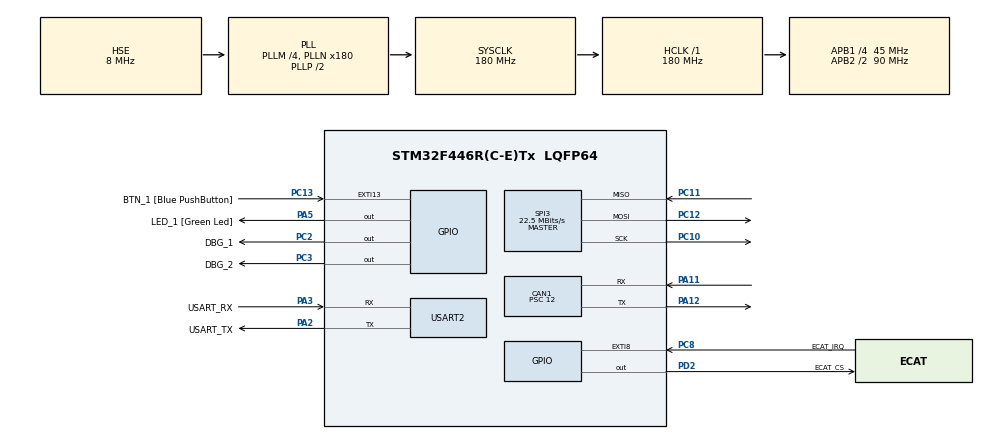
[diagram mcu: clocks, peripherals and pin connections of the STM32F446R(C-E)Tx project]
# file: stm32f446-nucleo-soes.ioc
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CAN1.AWUM=DISABLE
CAN1.BS1=CAN_BS1_12TQ
CAN1.BS2=CAN_BS2_2TQ
CAN1.CalculateBaudRate=250000
CAN1.CalculateTimeBit=4000
CAN1.CalculateTimeQuantum=266.6666666666667
CAN1.NART=DISABLE
CAN1.Prescaler=12
CAN1.RFLM=DISABLE
CAN1.SJW=CAN_SJW_1TQ
Mcu.Family=STM32F4
Mcu.Name=STM32F446R(C-E)Tx
Mcu.Package=LQFP64
Mcu.UserConstants=ecat_spi,$$_SPI3_IP_HANDLE_$$;printf_uart,$$_USART2_IP_HANDLE_$$
NVIC.CAN1_RX0_IRQn=true\:0\:0\:false\:false\:true\:true\:true\:true
NVIC.EXTI15_10_IRQn=true\:0\:0\:false\:false\:true\:true\:true\:true
NVIC.EXTI9_5_IRQn=true\:0\:0\:false\:false\:true\:true\:true\:true
NVIC.PriorityGroup=NVIC_PRIORITYGROUP_2
NVIC.TIM7_IRQn=true\:0\:0\:true\:false\:true\:true\:true\:true
PA11.Mode=CAN_Activate
PA11.Signal=CAN1_RX
PA12.Mode=CAN_Activate
PA12.Signal=CAN1_TX
PA13.GPIO_Label=TMS
PA13.Mode=Serial_Wire
PA13.Signal=SYS_JTMS-SWDIO
PA14.GPIO_Label=TCK
PA14.Mode=Serial_Wire
PA14.Signal=SYS_JTCK-SWCLK
PA2.GPIO_Label=USART_TX
PA2.Mode=Asynchronous
PA2.Signal=USART2_TX
PA3.GPIO_Label=USART_RX
PA3.Mode=Asynchronous
PA3.Signal=USART2_RX
PA5.GPIO_Label=LED_1 [Green Led]
PA5.Signal=GPIO_Output
PB3.GPIO_Label=SWO
PB3.Signal=SYS_JTDO-SWO
PC10.GPIO_Mode=GPIO_MODE_AF_PP
PC10.GPIO_PuPd=GPIO_NOPULL
PC10.GPIO_Speed=GPIO_SPEED_FREQ_VERY_HIGH
PC10.Mode=Full_Duplex_Master
PC10.Signal=SPI3_SCK
PC11.GPIO_Mode=GPIO_MODE_AF_PP
PC11.GPIO_PuPd=GPIO_NOPULL
PC11.GPIO_Speed=GPIO_SPEED_FREQ_VERY_HIGH
PC11.Mode=Full_Duplex_Master
PC11.Signal=SPI3_MISO
PC12.GPIO_Mode=GPIO_MODE_AF_PP
PC12.GPIO_PuPd=GPIO_NOPULL
PC12.GPIO_Speed=GPIO_SPEED_FREQ_VERY_HIGH
PC12.Mode=Full_Duplex_Master
PC12.Signal=SPI3_MOSI
PC13.GPIO_Label=BTN_1 [Blue PushButton]
PC13.GPIO_ModeDefaultEXTI=GPIO_MODE_IT_FALLING
PC13.Signal=GPXTI13
PC14-OSC32_IN.Mode=LSE-External-Oscillator
PC14-OSC32_IN.Signal=RCC_OSC32_IN
PC15-OSC32_OUT.Mode=LSE-External-Oscillator
PC15-OSC32_OUT.Signal=RCC_OSC32_OUT
PC2.GPIO_Label=DBG_1
PC2.Signal=GPIO_Output
PC3.GPIO_Label=DBG_2
PC3.Signal=GPIO_Output
PC8.GPIO_Label=ECAT_IRQ
PC8.Signal=GPXTI8
PD2.GPIO_Label=ECAT_CS
PD2.Signal=GPIO_Output
PH0-OSC_IN.Mode=HSE-External-Oscillator
PH0-OSC_IN.Signal=RCC_OSC_IN
PH1-OSC_OUT.Mode=HSE-External-Oscillator
PH1-OSC_OUT.Signal=RCC_OSC_OUT
ProjectManager.HeapSize=0x200
ProjectManager.StackSize=0x400
ProjectManager.TargetToolchain=CMake
RCC.48MHZClocksFreq_Value=84000000
RCC.AHBFreq_Value=180000000
RCC.APB1CLKDivider=RCC_HCLK_DIV4
RCC.APB1Freq_Value=45000000
RCC.APB1TimFreq_Value=90000000
RCC.APB2CLKDivider=RCC_HCLK_DIV2
RCC.APB2Freq_Value=90000000
RCC.APB2TimFreq_Value=180000000
RCC.CortexFreq_Value=180000000
RCC.FLatency-AdvancedSettings=FLASH_LATENCY_5
RCC.HCLKFreq_Value=180000000
RCC.HSE_VALUE=8000000
RCC.HSI_VALUE=16000000
RCC.PLLM=4
RCC.PLLN=180
RCC.PLLSourceVirtual=RCC_PLLSOURCE_HSE
RCC.SYSCLKFreq_VALUE=180000000
RCC.SYSCLKSource=RCC_SYSCLKSOURCE_PLLCLK
RCC.USBFreq_Value=180000000
RCC.VCOOutputFreq_Value=360000000
SPI3.BaudRatePrescaler=SPI_BAUDRATEPRESCALER_2
SPI3.CalculateBaudRate=22.5 MBits/s
SPI3.Direction=SPI_DIRECTION_2LINES
SPI3.Mode=SPI_MODE_MASTER
SPI3.VirtualType=VM_MASTER
TIM7.Period=44999
TIM7.Prescaler=1
USART2.VirtualMode=VM_ASYNC
VP_CRC_VS_CRC.Mode=CRC_Activate
VP_TIM7_VS_ClockSourceINT.Mode=Enable_Timer
board=NUCLEO-F446RE
PA11.GPIO_Speed=GPIO_SPEED_FREQ_VERY_HIGH
PA11.GPIO_PuPd=GPIO_NOPULL
PA11.GPIO_Mode=GPIO_MODE_AF_PP
PA12.GPIO_Speed=GPIO_SPEED_FREQ_VERY_HIGH
PA12.GPIO_PuPd=GPIO_NOPULL
PA12.GPIO_Mode=GPIO_MODE_AF_PP

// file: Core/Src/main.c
/* USER CODE BEGIN Header */
/**
  ******************************************************************************
  * @file           : main.c
  * @brief          : Main program body
  ******************************************************************************
  * @attention
  *
  * Copyright (c) 2024 STMicroelectronics.
  * All rights reserved.
  *
  * This software is licensed under terms that can be found in the LICENSE file
  * in the root directory of this software component.
  * If no LICENSE file comes with this software, it is provided AS-IS.
  *
  ******************************************************************************
  */
/* USER CODE END Header */
#include "main.h"

/* USER CODE BEGIN Includes */
extern const uint32_t g_pfnVectors[];
#include "user_code.h"
/* USER CODE END Includes */

CAN_HandleTypeDef hcan1;

CRC_HandleTypeDef hcrc;

SPI_HandleTypeDef hspi3;

TIM_HandleTypeDef htim7;

UART_HandleTypeDef huart2;

void SystemClock_Config(void);
static void MX_GPIO_Init(void);
static void MX_USART2_UART_Init(void);
static void MX_CRC_Init(void);
static void MX_CAN1_Init(void);
static void MX_SPI3_Init(void);
static void MX_TIM7_Init(void);

int main(void)
{

  /* USER CODE BEGIN 1 */
  /* Use this application vector table for bootloader and direct-debug entry. */
  SCB->VTOR = (uint32_t)g_pfnVectors;
  __DSB();
  __ISB();

  /* USER CODE END 1 */

  /* MCU Configuration--------------------------------------------------------*/

  /* Reset of all peripherals, Initializes the Flash interface and the Systick. */
  HAL_Init();

  /* Configure the system clock */
  SystemClock_Config();

  /* Initialize all configured peripherals */
  MX_GPIO_Init();
  MX_USART2_UART_Init();
  MX_CRC_Init();
  MX_SPI3_Init();
  MX_TIM7_Init();
  MX_CAN1_Init();
  /* USER CODE BEGIN 2 */
  user_code_init();
  /* USER CODE END 2 */

  /* Infinite loop */
  /* USER CODE BEGIN WHILE */
  while (1)
  {
	  user_code_loop();
    /* USER CODE END WHILE */

  }
}

void SystemClock_Config(void)
{
  RCC_OscInitTypeDef RCC_OscInitStruct = {0};
  RCC_ClkInitTypeDef RCC_ClkInitStruct = {0};

  /** Configure the main internal regulator output voltage
  */
  __HAL_RCC_PWR_CLK_ENABLE();
  __HAL_PWR_VOLTAGESCALING_CONFIG(PWR_REGULATOR_VOLTAGE_SCALE1);

  /** Initializes the RCC Oscillators according to the specified parameters
  * in the RCC_OscInitTypeDef structure.
  */
  RCC_OscInitStruct.OscillatorType = RCC_OSCILLATORTYPE_HSE;
  RCC_OscInitStruct.HSEState = RCC_HSE_ON;
  RCC_OscInitStruct.PLL.PLLState = RCC_PLL_ON;
  RCC_OscInitStruct.PLL.PLLSource = RCC_PLLSOURCE_HSE;
  RCC_OscInitStruct.PLL.PLLM = 4;
  RCC_OscInitStruct.PLL.PLLN = 180;
  RCC_OscInitStruct.PLL.PLLP = RCC_PLLP_DIV2;
  RCC_OscInitStruct.PLL.PLLQ = 2;
  RCC_OscInitStruct.PLL.PLLR = 2;
  if (HAL_RCC_OscConfig(&RCC_OscInitStruct) != HAL_OK)
  {
    Error_Handler();
  }

  /** Activate the Over-Drive mode
  */
  if (HAL_PWREx_EnableOverDrive() != HAL_OK)
  {
    Error_Handler();
  }

  /** Initializes the CPU, AHB and APB buses clocks
  */
  RCC_ClkInitStruct.ClockType = RCC_CLOCKTYPE_HCLK|RCC_CLOCKTYPE_SYSCLK
                              |RCC_CLOCKTYPE_PCLK1|RCC_CLOCKTYPE_PCLK2;
  RCC_ClkInitStruct.SYSCLKSource = RCC_SYSCLKSOURCE_PLLCLK;
  RCC_ClkInitStruct.AHBCLKDivider = RCC_SYSCLK_DIV1;
  RCC_ClkInitStruct.APB1CLKDivider = RCC_HCLK_DIV4;
  RCC_ClkInitStruct.APB2CLKDivider = RCC_HCLK_DIV2;

  if (HAL_RCC_ClockConfig(&RCC_ClkInitStruct, FLASH_LATENCY_5) != HAL_OK)
  {
    Error_Handler();
  }
}

static void MX_CAN1_Init(void)
{

  hcan1.Instance = CAN1;
  hcan1.Init.Prescaler = 12;
  hcan1.Init.Mode = CAN_MODE_NORMAL;
  hcan1.Init.SyncJumpWidth = CAN_SJW_1TQ;
  hcan1.Init.TimeSeg1 = CAN_BS1_12TQ;
  hcan1.Init.TimeSeg2 = CAN_BS2_2TQ;
  hcan1.Init.TimeTriggeredMode = DISABLE;
  hcan1.Init.AutoBusOff = DISABLE;
  hcan1.Init.AutoWakeUp = DISABLE;
  hcan1.Init.AutoRetransmission = DISABLE;
  hcan1.Init.ReceiveFifoLocked = DISABLE;
  hcan1.Init.TransmitFifoPriority = DISABLE;
  if (HAL_CAN_Init(&hcan1) != HAL_OK)
  {
    Error_Handler();
  }

}

static void MX_CRC_Init(void)
{

  hcrc.Instance = CRC;
  if (HAL_CRC_Init(&hcrc) != HAL_OK)
  {
    Error_Handler();
  }

}

static void MX_SPI3_Init(void)
{

  /* SPI3 parameter configuration*/
  hspi3.Instance = SPI3;
  hspi3.Init.Mode = SPI_MODE_MASTER;
  hspi3.Init.Direction = SPI_DIRECTION_2LINES;
  hspi3.Init.DataSize = SPI_DATASIZE_8BIT;
  hspi3.Init.CLKPolarity = SPI_POLARITY_LOW;
  hspi3.Init.CLKPhase = SPI_PHASE_1EDGE;
  hspi3.Init.NSS = SPI_NSS_SOFT;
  hspi3.Init.BaudRatePrescaler = SPI_BAUDRATEPRESCALER_2;
  hspi3.Init.FirstBit = SPI_FIRSTBIT_MSB;
  hspi3.Init.TIMode = SPI_TIMODE_DISABLE;
  hspi3.Init.CRCCalculation = SPI_CRCCALCULATION_DISABLE;
  hspi3.Init.CRCPolynomial = 10;
  if (HAL_SPI_Init(&hspi3) != HAL_OK)
  {
    Error_Handler();
  }

}

static void MX_TIM7_Init(void)
{

  TIM_MasterConfigTypeDef sMasterConfig = {0};

  htim7.Instance = TIM7;
  htim7.Init.Prescaler = 1;
  htim7.Init.CounterMode = TIM_COUNTERMODE_UP;
  htim7.Init.Period = 44999;
  htim7.Init.AutoReloadPreload = TIM_AUTORELOAD_PRELOAD_DISABLE;
  if (HAL_TIM_Base_Init(&htim7) != HAL_OK)
  {
    Error_Handler();
  }
  sMasterConfig.MasterOutputTrigger = TIM_TRGO_RESET;
  sMasterConfig.MasterSlaveMode = TIM_MASTERSLAVEMODE_DISABLE;
  if (HAL_TIMEx_MasterConfigSynchronization(&htim7, &sMasterConfig) != HAL_OK)
  {
    Error_Handler();
  }

}

static void MX_USART2_UART_Init(void)
{

  huart2.Instance = USART2;
  huart2.Init.BaudRate = 115200;
  huart2.Init.WordLength = UART_WORDLENGTH_8B;
  huart2.Init.StopBits = UART_STOPBITS_1;
  huart2.Init.Parity = UART_PARITY_NONE;
  huart2.Init.Mode = UART_MODE_TX_RX;
  huart2.Init.HwFlowCtl = UART_HWCONTROL_NONE;
  huart2.Init.OverSampling = UART_OVERSAMPLING_16;
  if (HAL_UART_Init(&huart2) != HAL_OK)
  {
    Error_Handler();
  }

}

static void MX_GPIO_Init(void)
{
  GPIO_InitTypeDef GPIO_InitStruct = {0};

  /* GPIO Ports Clock Enable */
  __HAL_RCC_GPIOC_CLK_ENABLE();
  __HAL_RCC_GPIOH_CLK_ENABLE();
  __HAL_RCC_GPIOA_CLK_ENABLE();
  __HAL_RCC_GPIOD_CLK_ENABLE();
  __HAL_RCC_GPIOB_CLK_ENABLE();

  /*Configure GPIO pin Output Level */
  HAL_GPIO_WritePin(GPIOC, DBG_1_Pin|DBG_2_Pin, GPIO_PIN_RESET);

  /*Configure GPIO pin Output Level */
  HAL_GPIO_WritePin(LED_1_GPIO_Port, LED_1_Pin, GPIO_PIN_RESET);

  /*Configure GPIO pin Output Level */
  HAL_GPIO_WritePin(ECAT_CS_GPIO_Port, ECAT_CS_Pin, GPIO_PIN_RESET);

  /*Configure GPIO pin : BTN_1_Pin */
  GPIO_InitStruct.Pin = BTN_1_Pin;
  GPIO_InitStruct.Mode = GPIO_MODE_IT_FALLING;
  GPIO_InitStruct.Pull = GPIO_NOPULL;
  HAL_GPIO_Init(BTN_1_GPIO_Port, &GPIO_InitStruct);

  /*Configure GPIO pins : DBG_1_Pin DBG_2_Pin */
  GPIO_InitStruct.Pin = DBG_1_Pin|DBG_2_Pin;
  GPIO_InitStruct.Mode = GPIO_MODE_OUTPUT_PP;
  GPIO_InitStruct.Pull = GPIO_NOPULL;
  GPIO_InitStruct.Speed = GPIO_SPEED_FREQ_LOW;
  HAL_GPIO_Init(GPIOC, &GPIO_InitStruct);

  /*Configure GPIO pin : LED_1_Pin */
  GPIO_InitStruct.Pin = LED_1_Pin;
  GPIO_InitStruct.Mode = GPIO_MODE_OUTPUT_PP;
  GPIO_InitStruct.Pull = GPIO_NOPULL;
  GPIO_InitStruct.Speed = GPIO_SPEED_FREQ_LOW;
  HAL_GPIO_Init(LED_1_GPIO_Port, &GPIO_InitStruct);

  /*Configure GPIO pin : ECAT_IRQ_Pin */
  GPIO_InitStruct.Pin = ECAT_IRQ_Pin;
  GPIO_InitStruct.Mode = GPIO_MODE_IT_RISING;
  GPIO_InitStruct.Pull = GPIO_NOPULL;
  HAL_GPIO_Init(ECAT_IRQ_GPIO_Port, &GPIO_InitStruct);

  /*Configure GPIO pin : ECAT_CS_Pin */
  GPIO_InitStruct.Pin = ECAT_CS_Pin;
  GPIO_InitStruct.Mode = GPIO_MODE_OUTPUT_PP;
  GPIO_InitStruct.Pull = GPIO_NOPULL;
  GPIO_InitStruct.Speed = GPIO_SPEED_FREQ_LOW;
  HAL_GPIO_Init(ECAT_CS_GPIO_Port, &GPIO_InitStruct);

  /* EXTI interrupt init*/
  HAL_NVIC_SetPriority(EXTI15_10_IRQn, 0, 0);
  HAL_NVIC_EnableIRQ(EXTI15_10_IRQn);
  HAL_NVIC_SetPriority(EXTI9_5_IRQn, 0, 0);
  HAL_NVIC_EnableIRQ(EXTI9_5_IRQn);

}

void Error_Handler(void)
{
  __disable_irq();
  while (1)
  {
  }
}
